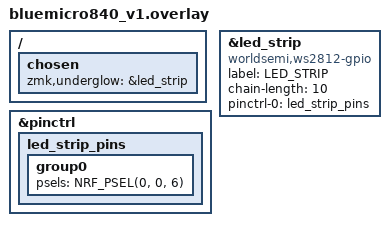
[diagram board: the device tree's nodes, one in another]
&pinctrl {
    led_strip_pins: led_strip_pins {
        group0 {
            psels = <NRF_PSEL(0, 0, 6)>; // Change to your LED strip data pin
        };
    };
};

&led_strip {
    compatible = "worldsemi,ws2812-gpio"; // Use "ws2812-spi" if using SPI
    label = "LED_STRIP";
    chain-length = <10>;  // Set to your number of LEDs
    pinctrl-0 = <&led_strip_pins>; // Reference the correct pinctrl group
    pinctrl-names = "default";
    status = "okay";
};

/ {
    chosen {
        zmk,underglow = &led_strip;
    };
};
